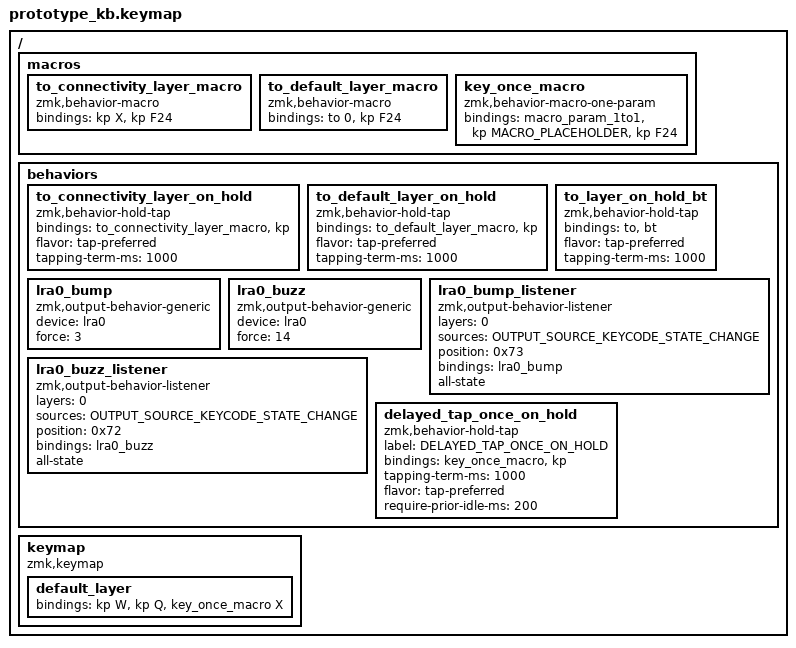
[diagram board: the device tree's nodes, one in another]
/*
 * Copyright (c) 2022 The ZMK Contributors
 *
 * SPDX-License-Identifier: MIT
 */

#include <behaviors.dtsi>
#include <dt-bindings/zmk/keys.h>
#include <dt-bindings/zmk/bt.h>
#define OUTPUT_SOURCE_KEYCODE_STATE_CHANGE      3

/ {
    macros {
        to_connectivity_layer_macro: to_connectivity_layer_macro {
            compatible = "zmk,behavior-macro";
            #binding-cells = <0>;
            bindings = <&kp X>, <&kp F24>;
        };

        to_default_layer_macro: to_default_layer_macro {
            compatible = "zmk,behavior-macro";
            #binding-cells = <0>;
            bindings = <&to 0>, <&kp F24>;
        };

        key_once_macro: key_once_macro {
            compatible = "zmk,behavior-macro-one-param";
            #binding-cells = <1>;
            bindings = <&macro_param_1to1>, <&kp MACRO_PLACEHOLDER>, <&kp F24>;
        };
    };

    behaviors {
        to_connectivity_layer_on_hold: to_connectivity_layer_on_hold {
            compatible = "zmk,behavior-hold-tap";
            bindings = <&to_connectivity_layer_macro>, <&kp>;

            #binding-cells = <2>;
            flavor = "tap-preferred";
            tapping-term-ms = <1000>;
        };

        to_default_layer_on_hold: to_default_layer_on_hold {
            compatible = "zmk,behavior-hold-tap";
            bindings = <&to_default_layer_macro>, <&kp>;

            #binding-cells = <2>;
            flavor = "tap-preferred";
            tapping-term-ms = <1000>;
        };

        to_layer_on_hold_bt: to_layer_on_hold_bt {
            compatible = "zmk,behavior-hold-tap";
            bindings = <&to>, <&bt>;

            #binding-cells = <2>;
            flavor = "tap-preferred";
            tapping-term-ms = <1000>;
        };

        lra0_bump: lra0_bump {
            compatible = "zmk,output-behavior-generic"; 
            #binding-cells = <0>;
            device = <&lra0>;
            /* force will be convrt to waveformm effect from DRV2605 library */
            /* NOTE: <7> is Soft Bump at 100% */
            force = <3>;
        };

        lra0_buzz: lra0_buzz {
            compatible = "zmk,output-behavior-generic"; 
            #binding-cells = <0>;
            device = <&lra0>;
            /* force will be convrt to waveformm effect from DRV2605 library */
            /* NOTE: <7> is Soft Bump at 100% */
            force = <14>;
        };

        lra0_bump_listener: lra0_bump_listener {
            compatible = "zmk,output-behavior-listener";
            layers = < 0 >;
            sources = < OUTPUT_SOURCE_KEYCODE_STATE_CHANGE >;
            #binding-cells = <0>;
            /* set keycode filter here */
            position = < 0x73 >;
            bindings = < &lra0_bump >;
            
            /* enable to catch all state change that include key press and release */
            /* ensure to stop on-going LRA effect immediately on key released */
            all-state;
        };

        lra0_buzz_listener: lra0_buzz_listener {
            compatible = "zmk,output-behavior-listener";
            layers = < 0 >;
            sources = < OUTPUT_SOURCE_KEYCODE_STATE_CHANGE >;
            #binding-cells = <0>;
            /* set keycode filter here */
            position = < 0x72 >;
            bindings = < &lra0_buzz >;
            
            /* enable to catch all state change that include key press and release */
            /* ensure to stop on-going LRA effect immediately on key released */
            all-state;
        };

        delayed_tap_once_on_hold: delayed_tap_once_on_hold {
            compatible = "zmk,behavior-hold-tap";
            label = "DELAYED_TAP_ONCE_ON_HOLD";
            bindings = <&key_once_macro>, <&kp>;

            #binding-cells = <2>;
            tapping-term-ms = <1000>;
            flavor = "tap-preferred";
            require-prior-idle-ms = <200>;
        };
    };

    

    keymap {
        compatible = "zmk,keymap";

        default_layer {
            bindings = <
                &kp W
                &kp Q
                &key_once_macro X
            >;
        };
    };  
};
